AUTOSAR XML (schema 00048)
package /HuaweiMDC/FunctionalSoftware/Planning/Execution
  executable planning_execute
    root sw component prototype planning_root_swc: application-type=planning_base
package /HuaweiMDC/FunctionalSoftware/Planning/SwComponent
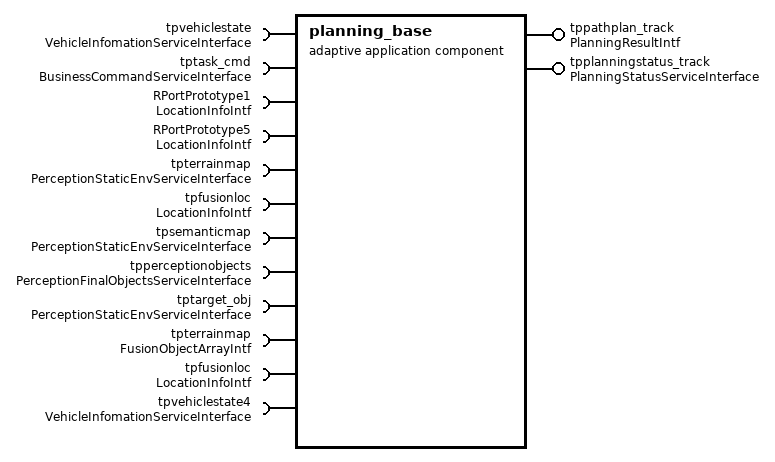
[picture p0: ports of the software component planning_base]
  adaptive application sw component type planning_base
    provide port tppathplan_track: provided-interface=PlanningResultIntf
    provide port tpplanningstatus_track: provided-interface=PlanningStatusServiceInterface
    12 x require port:
      tpvehiclestate: required-interface=VehicleInfomationServiceInterface
      tptask_cmd: required-interface=BusinessCommandServiceInterface
      RPortPrototype1: required-interface=LocationInfoIntf
      RPortPrototype5: required-interface=LocationInfoIntf
      tpterrainmap: required-interface=PerceptionStaticEnvServiceInterface
      tpfusionloc: required-interface=LocationInfoIntf
      tpsemanticmap: required-interface=PerceptionStaticEnvServiceInterface
      tpperceptionobjects: required-interface=PerceptionFinalObjectsServiceInterface
      tptarget_obj: required-interface=PerceptionStaticEnvServiceInterface
      tpterrainmap: required-interface=FusionObjectArrayIntf
      tpfusionloc: required-interface=LocationInfoIntf
      tpvehiclestate4: required-interface=VehicleInfomationServiceInterface
